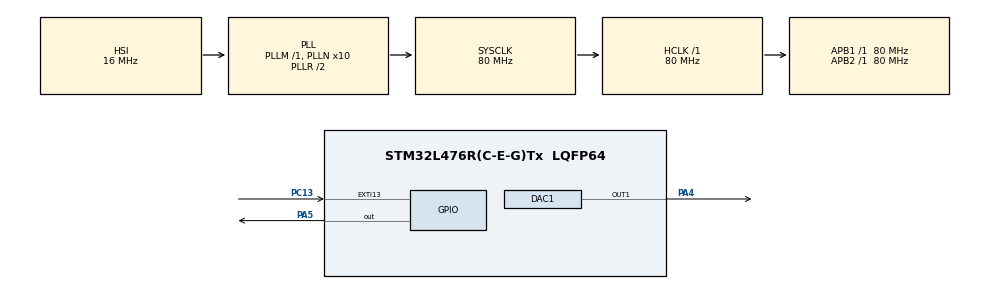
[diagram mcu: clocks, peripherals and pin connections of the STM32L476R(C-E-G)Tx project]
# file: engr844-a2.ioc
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DAC1.DAC_Trigger-DAC_OUT1=DAC_TRIGGER_T6_TRGO
Dma.DAC_CH1.0.Direction=DMA_MEMORY_TO_PERIPH
Dma.DAC_CH1.0.Instance=DMA1_Channel3
Dma.DAC_CH1.0.MemDataAlignment=DMA_MDATAALIGN_HALFWORD
Dma.DAC_CH1.0.MemInc=DMA_MINC_ENABLE
Dma.DAC_CH1.0.Mode=DMA_CIRCULAR
Dma.DAC_CH1.0.PeriphDataAlignment=DMA_PDATAALIGN_HALFWORD
Dma.DAC_CH1.0.PeriphInc=DMA_PINC_DISABLE
Dma.DAC_CH1.0.Priority=DMA_PRIORITY_LOW
Dma.Request0=DAC_CH1
FREERTOS.Tasks01=defaultTask,24,128,StartDefaultTask,Default,NULL,Dynamic,NULL,NULL
FREERTOS.configUSE_NEWLIB_REENTRANT=1
Mcu.Family=STM32L4
Mcu.Name=STM32L476R(C-E-G)Tx
Mcu.Package=LQFP64
NUCLEO-L476RG.BUTTON=1
NUCLEO-L476RG.LD2=true
NVIC.DMA1_Channel3_IRQn=true\:5\:0\:false\:false\:true\:true\:false\:true\:true
NVIC.EXTI15_10_IRQn=true\:5\:0\:false\:false\:true\:true\:false\:true\:true
NVIC.PriorityGroup=NVIC_PRIORITYGROUP_4
NVIC.TIM1_UP_TIM16_IRQn=true\:15\:0\:false\:false\:true\:false\:false\:true\:true
NVIC.TimeBase=TIM1_UP_TIM16_IRQn
NVIC.TimeBaseIP=TIM1
PA13\ (JTMS-SWDIO).GPIO_Label=TMS
PA13\ (JTMS-SWDIO).Signal=SYS_JTMS-SWDIO
PA14\ (JTCK-SWCLK).GPIO_Label=TCK
PA14\ (JTCK-SWCLK).Signal=SYS_JTCK-SWCLK
PA2.GPIO_Label=USART_TX
PA2.GPIO_Mode=GPIO_MODE_AF_PP
PA2.GPIO_PuPd=GPIO_NOPULL
PA2.GPIO_Speed=GPIO_SPEED_FREQ_VERY_HIGH
PA2.Signal=USART2_TX
PA3.GPIO_Label=USART_RX
PA3.GPIO_Mode=GPIO_MODE_AF_PP
PA3.GPIO_PuPd=GPIO_NOPULL
PA3.GPIO_Speed=GPIO_SPEED_FREQ_VERY_HIGH
PA3.Signal=USART2_RX
PA4.Signal=COMP_DAC11_group
PA5.Signal=GPIO_Output
PB3\ (JTDO-TRACESWO).GPIO_Label=SWO
PB3\ (JTDO-TRACESWO).Signal=SYS_JTDO-SWO
PC13.Signal=GPXTI13
PC14-OSC32_IN\ (PC14).Signal=RCC_OSC32_IN
PC15-OSC32_OUT\ (PC15).Signal=RCC_OSC32_OUT
PH0-OSC_IN\ (PH0).Signal=RCC_OSC_IN
PH1-OSC_OUT\ (PH1).Signal=RCC_OSC_OUT
ProjectManager.HeapSize=0x200
ProjectManager.StackSize=0x400
ProjectManager.TargetToolchain=STM32CubeIDE
RCC.ADCFreq_Value=64000000
RCC.AHBFreq_Value=80000000
RCC.APB1Freq_Value=80000000
RCC.APB1TimFreq_Value=80000000
RCC.APB2Freq_Value=80000000
RCC.APB2TimFreq_Value=80000000
RCC.CortexFreq_Value=80000000
RCC.HCLKFreq_Value=80000000
RCC.HSE_VALUE=8000000
RCC.HSI_VALUE=16000000
RCC.LSE_VALUE=32768
RCC.MSI_VALUE=4000000
RCC.PLLN=10
RCC.PLLSourceVirtual=RCC_PLLSOURCE_HSI
RCC.PREFETCH_ENABLE=1
RCC.SYSCLKFreq_VALUE=80000000
RCC.SYSCLKSource=RCC_SYSCLKSOURCE_PLLCLK
RCC.USBFreq_Value=64000000
RCC.VCOOutputFreq_Value=160000000
SH.COMP_DAC11_group.0=DAC1_OUT1,DAC_OUT1
TIM6.Period=624
TIM6.TIM_MasterOutputTrigger=TIM_TRGO_UPDATE
VP_FREERTOS_VS_CMSIS_V2.Mode=CMSIS_V2
VP_NUCLEO-L476RG_VS_BSP_COMMON.Mode=COMMON
VP_SYS_VS_tim1.Mode=TIM1
VP_TIM6_VS_ClockSourceINT.Mode=Enable_Timer
board=NUCLEO-L476RG

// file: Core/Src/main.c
/* USER CODE BEGIN Header */
/**
  ******************************************************************************
  * @file           : main.c
  * @brief          : Main program body
  ******************************************************************************
  * @attention
  *
  * Copyright (c) 2026 STMicroelectronics.
  * All rights reserved.
  *
  * This software is licensed under terms that can be found in the LICENSE file
  * in the root directory of this software component.
  * If no LICENSE file comes with this software, it is provided AS-IS.
  *
  ******************************************************************************
  */
/* USER CODE END Header */
#include "main.h"
#include "cmsis_os.h"
#include "dac.h"
#include "dma.h"
#include "tim.h"
#include "gpio.h"

void SystemClock_Config(void);
void MX_FREERTOS_Init(void);

int main(void)
{

  /* MCU Configuration--------------------------------------------------------*/

  /* Reset of all peripherals, Initializes the Flash interface and the Systick. */
  HAL_Init();

  /* Configure the system clock */
  SystemClock_Config();

  /* Initialize all configured peripherals */
  MX_GPIO_Init();
  MX_DMA_Init();
  MX_DAC1_Init();
  MX_TIM6_Init();

  /* Init scheduler */
  osKernelInitialize();  /* Call init function for freertos objects (in cmsis_os2.c) */
  MX_FREERTOS_Init();

  /* Initialize leds */
  BSP_LED_Init(LED_GREEN);

  /* Initialize USER push-button, will be used to trigger an interrupt each time it's pressed.*/
  BSP_PB_Init(BUTTON_USER, BUTTON_MODE_EXTI);

  /* Start scheduler */
  osKernelStart();

  /* We should never get here as control is now taken by the scheduler */

  /* Infinite loop */
  while (1)
  {

  }
}

void SystemClock_Config(void)
{
  RCC_OscInitTypeDef RCC_OscInitStruct = {0};
  RCC_ClkInitTypeDef RCC_ClkInitStruct = {0};

  /** Configure the main internal regulator output voltage
  */
  if (HAL_PWREx_ControlVoltageScaling(PWR_REGULATOR_VOLTAGE_SCALE1) != HAL_OK)
  {
    Error_Handler();
  }

  /** Initializes the RCC Oscillators according to the specified parameters
  * in the RCC_OscInitTypeDef structure.
  */
  RCC_OscInitStruct.OscillatorType = RCC_OSCILLATORTYPE_HSI;
  RCC_OscInitStruct.HSIState = RCC_HSI_ON;
  RCC_OscInitStruct.HSICalibrationValue = RCC_HSICALIBRATION_DEFAULT;
  RCC_OscInitStruct.PLL.PLLState = RCC_PLL_ON;
  RCC_OscInitStruct.PLL.PLLSource = RCC_PLLSOURCE_HSI;
  RCC_OscInitStruct.PLL.PLLM = 1;
  RCC_OscInitStruct.PLL.PLLN = 10;
  RCC_OscInitStruct.PLL.PLLP = RCC_PLLP_DIV7;
  RCC_OscInitStruct.PLL.PLLQ = RCC_PLLQ_DIV2;
  RCC_OscInitStruct.PLL.PLLR = RCC_PLLR_DIV2;
  if (HAL_RCC_OscConfig(&RCC_OscInitStruct) != HAL_OK)
  {
    Error_Handler();
  }

  /** Initializes the CPU, AHB and APB buses clocks
  */
  RCC_ClkInitStruct.ClockType = RCC_CLOCKTYPE_HCLK|RCC_CLOCKTYPE_SYSCLK
                              |RCC_CLOCKTYPE_PCLK1|RCC_CLOCKTYPE_PCLK2;
  RCC_ClkInitStruct.SYSCLKSource = RCC_SYSCLKSOURCE_PLLCLK;
  RCC_ClkInitStruct.AHBCLKDivider = RCC_SYSCLK_DIV1;
  RCC_ClkInitStruct.APB1CLKDivider = RCC_HCLK_DIV1;
  RCC_ClkInitStruct.APB2CLKDivider = RCC_HCLK_DIV1;

  if (HAL_RCC_ClockConfig(&RCC_ClkInitStruct, FLASH_LATENCY_4) != HAL_OK)
  {
    Error_Handler();
  }
}

void HAL_TIM_PeriodElapsedCallback(TIM_HandleTypeDef *htim)
{
  if (htim->Instance == TIM1)
  {
    HAL_IncTick();
  }
}

void Error_Handler(void)
{
  __disable_irq();
  while (1)
  {
  }
}

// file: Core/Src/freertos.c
/* USER CODE BEGIN Header */
/**
  ******************************************************************************
  * File Name          : freertos.c
  * Description        : Code for freertos applications
  ******************************************************************************
  * @attention
  *
  * Copyright (c) 2026 STMicroelectronics.
  * All rights reserved.
  *
  * This software is licensed under terms that can be found in the LICENSE file
  * in the root directory of this software component.
  * If no LICENSE file comes with this software, it is provided AS-IS.
  *
  ******************************************************************************
  */
/* USER CODE END Header */

#include "FreeRTOS.h"
#include "task.h"
#include "main.h"
#include "cmsis_os.h"

/* USER CODE BEGIN Includes */
#include "dac.h"
#include "tim.h"
#include <math.h>
/* USER CODE END Includes */

/* USER CODE BEGIN Variables */
#define SINE_SAMPLES 128U
#define DAC_MIDPOINT 2048U
#define DAC_AMPLITUDE 1800U

uint16_t sine_table[SINE_SAMPLES];

static void SineTable_Init(void)
{
  for (uint32_t i = 0; i < SINE_SAMPLES; i++)
  {
    float angle =
        2.0f * 3.14159265359f *
        ((float)i / (float)SINE_SAMPLES);

    sine_table[i] =
        (uint16_t)(DAC_MIDPOINT +
        DAC_AMPLITUDE * sinf(angle));
  }
}
#define TIM6_CLOCK_HZ 80000000UL

static void Sine_SetFrequency(uint32_t frequency_hz)
{
    uint32_t sample_rate = SINE_SAMPLES * frequency_hz;
    uint32_t arr =
        (TIM6_CLOCK_HZ / sample_rate) - 1U;

    HAL_TIM_Base_Stop(&htim6);

    __HAL_TIM_SET_AUTORELOAD(&htim6, arr);
    __HAL_TIM_SET_COUNTER(&htim6, 0);

    HAL_TIM_Base_Start(&htim6);
}
/* USER CODE END Variables */
/* Definitions for defaultTask */
osThreadId_t defaultTaskHandle;
const osThreadAttr_t defaultTask_attributes = {
  .name = "defaultTask",
  .stack_size = 128 * 4,
  .priority = (osPriority_t) osPriorityNormal,
};

void StartDefaultTask(void *argument);

void MX_FREERTOS_Init(void); /* (MISRA C 2004 rule 8.1) */

void MX_FREERTOS_Init(void) {

  /* Create the thread(s) */
  /* creation of defaultTask */
  defaultTaskHandle = osThreadNew(StartDefaultTask, NULL, &defaultTask_attributes);

}

void StartDefaultTask(void *argument)
{
  /* USER CODE BEGIN StartDefaultTask */
    SineTable_Init();

    HAL_DAC_Start_DMA(
        &hdac1,
        DAC_CHANNEL_1,
        (uint32_t *)sine_table,
        SINE_SAMPLES,
        DAC_ALIGN_12B_R
    );

    Sine_SetFrequency(2000);   // Generate approximately 20 kHz
  /* Infinite loop */
  for(;;)
  {
    osDelay(1000);
  }
  /* USER CODE END StartDefaultTask */
}
